# cyt4dn register map
Vendor: Cypress Semiconductor; Series: cyt4dn; File version: 1.0
CPU: CM7 r0p1, little endian, MPU, FPU, VTOR, 3 interrupt priority bits
Registers are 32-bit, read-write, reset 0x0 unless marked. A register's access mark holds for its fields unless they carry their own. Offsets are from the block's base; [hi:lo] are bit positions; lines under a group give offsets from that group; {n}, {i} and the like mark numbered series; 'fields as' and 'values as' point back to an identical list.

## VIDEOSS0 (part 10 of 18) — Video and Graphics Subsystem IP
Base 0x40A00000
0x80000 VIDEOIO group — Video I/O Core
  0x00 SUBIO group — Sub Interface
    0x10000 COMPENG group — Composition Engine
      0x7000 GPSCALER4 group — GPscaler #4 (Capture)
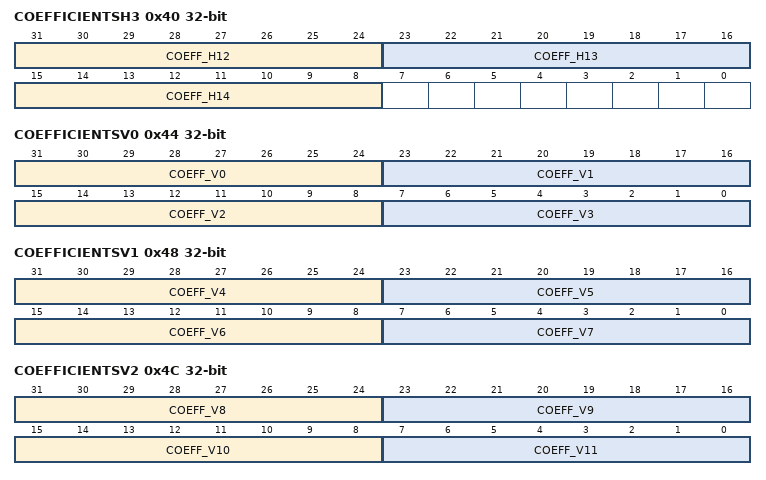
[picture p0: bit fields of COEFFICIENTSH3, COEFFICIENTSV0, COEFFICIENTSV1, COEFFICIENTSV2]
        0x40 COEFFICIENTSH3 — Horizontal coefficients for filter_mode FIR.
          [31:24] COEFF_H12 — Horizontal coefficient 12. (format is signed integer)
          [23:16] COEFF_H13 — Horizontal coefficient 13. (format is signed integer)
          [15:8] COEFF_H14 — Horizontal coefficient 14. The rightmost coefficient regardless of the filter width. In contrast to the coeff_h0 this coefficient has to be always programmed. (format is signed integer)
        0x44 COEFFICIENTSV0 — Vertical coefficients for filter_mode FIR.
          [31-8n:24-8n] COEFF_V{n} (n=0..3) — Vertical coefficient {n}. (format is signed integer)
        0x48 COEFFICIENTSV1 — Vertical coefficients for filter_mode FIR.
          [63-8n:56-8n] COEFF_V{n} (n=4..7) — Vertical coefficient {n}. (format is signed integer)
        0x4C COEFFICIENTSV2 — Vertical coefficients for filter_mode FIR.
          [95-8n:88-8n] COEFF_V{n} (n=8..11) — Vertical coefficient {n}. (format is signed integer)
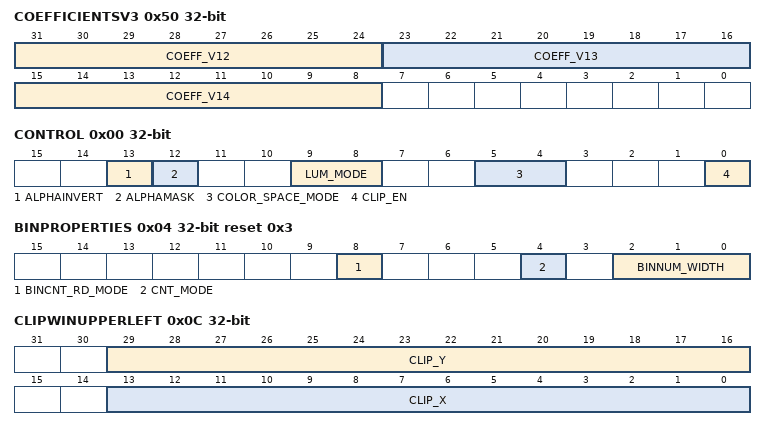
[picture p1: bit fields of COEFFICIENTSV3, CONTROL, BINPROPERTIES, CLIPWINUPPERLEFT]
        0x50 COEFFICIENTSV3 — Vertical coefficients for filter_mode FIR.
          [31:24] COEFF_V12 — Vertical coefficient 12. (format is signed integer)
          [23:16] COEFF_V13 — Vertical coefficient 13. (format is signed integer)
          [15:8] COEFF_V14 — Vertical coefficient 14. The bottommost coefficient regardless of the filter height. In contrast to the coeff_v0 this coefficient has to be always programmed. (format is signed integer)
      0x7400 HISTOGRAM4 group — Video Processing Block #0 Histogram (Capture)
        0x00 CONTROL — Controls some settings concerning input components and alpha mask.
          [13] ALPHAINVERT — Value 1 inverts the effect of the alpha mask mode when enabled (pixels with alpha value smaller or equal 0.5 are affecting the histogram bins).
          [12] ALPHAMASK — Value 1 enables the alpha mask mode. In this mode only pixels with an alpha value larger than 0.5 are affecting the histogram bins.
          [9:8] LUM_MODE — If a histogram for luma or luminance is required, the conversion formula for luma (Y component according to BT.601) or luminance (Y component according to BT.709) can be selected here. Luma or luminance calculation should only be applied if RGB components in range [0..255] are delivered directly at histogram input or when YCrCb components are converted to RGB by the appropriate setting of register field color_space_mode. Luma or luminance counting is delivered in first (component0) histogram. (format is unsigned integer)
            0=NO_CONV (Component0 for first histogram is counted as it is.); 1=LUMA (Component0 for first histogram is replaced by luma, which is calculated from RGB input components according to BT.601.); 2=LUMINANCE (Component0 for first histogram is replaced by luminance, which is calculated from RGB input components according to BT.709.)
          [5:4] COLOR_SPACE_MODE — Assuming that YUV(YCrCb) color components according to BT.601 or BT.709 are provided at histogram input the appropriate conversion to RGB components in [0,255] range can be selected here. (format is unsigned integer)
            0=NO_CONV (No color space conversion of input components is applied.); 1=YUV2RGB_BT601 (YUV input components as described in BT.601 are converted to RGB in [0,255] range.); 2=YUV2RGB_BT709 (YUV input components as described in BT.709 are converted to RGB in [0,255] range.)
          [0] CLIP_EN — Switch for clip window. If enabled all pixels outside the clip window are not taken into account. (format is unsigned integer)
            0=DISABLE (Clip window is switched off.); 1=ENABLE (Clip window is switched on.)
        0x04 BINPROPERTIES reset 0x3 — Configures the histogram bins.
          [8] BINCNT_RD_MODE — The field controls if the actual bin count or the sum of all bin counts up to actual bin count is provided in registers RsltComp0Bincnt, RsltComp1Bincnt and RsltComp2Bincnt. (format is unsigned integer)
            0=BINCNT (Actual bin cnt is provided.); 1=BINCNT_ACCU (Bin count sum is provided.)
          [4] CNT_MODE — Counter mode, which controls the way the bin values are accumulated. (format is unsigned integer)
            0=NEAREST (Counter of nearest bin is incremented.); 1=LINEAR (Counters of the 2 nearest bins are increased by one minus the distance to bin center (normalized between 0 and 1), it works only for first (component0) histogram, reading of component1/2 histogram results in undefined data.)
          [2:0] BINNUM_WIDTH — 2**binnum_width is the number of bins in a histogram. (format is unsigned integer)
            3=BINS_8 (There are 8 bins, addressable with 3bit.); 4=BINS_16 (There are 16 bins, addressable with 4bit.); 5=BINS_32 (There are 32 bins, addressable with 5bit.); 6=BINS_64 (There are 64 bins, addressable with 6bit.)
        0x08 BINCNTTHRESH — Bin counter threshold value.
          [28:0] BINCNT_THRESH — Bin counters below this threshold will be reported as 0. This threshold value will also affect the BINCNT_ACCU mode where 0 will be added for all bin counters below the threshold. (format is unsigned integer)
        0x0C CLIPWINUPPERLEFT — Coordinates of upper left corner of clip window.
          [29:16] CLIP_Y — Y coordinate of upper left corner of clip window. (format is unsigned integer)
          [13:0] CLIP_X — X coordinate of upper left corner of clip window. (format is unsigned integer)
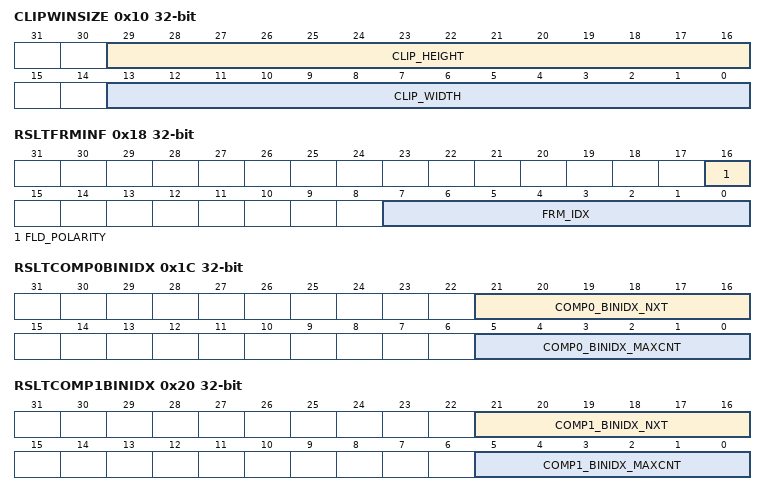
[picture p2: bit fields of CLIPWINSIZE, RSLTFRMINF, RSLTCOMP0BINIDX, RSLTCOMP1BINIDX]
        0x10 CLIPWINSIZE — Dimensions of clip window.
          [29:16] CLIP_HEIGHT — Height of clip window, given minus one. (format is unsigned integer)
          [13:0] CLIP_WIDTH — Width of clip window, given minus one. (format is unsigned integer)
        0x14 RSLTRDY ro — Measurement result status.
          [0] RSLT_RDY — A one indicates that measurement results (in registers Rslt...) are valid and can be read. (format is unsigned integer)
        0x18 RSLTFRMINF ro — Additional information on the measurement results.
          [16] FLD_POLARITY — Returns field polarity of the measured frame. This read value of this field is undefined in display stream context; use in storage, content or safety stream context only. (format is unsigned integer)
          [7:0] FRM_IDX — Each frame passing the histogram unit gets an index, which is the value of a wrapped around counter, which counts the frames independent from how the histogram unit is configured. The index of the frame of the ongoing readout can be read here. In display stream context, if the display operation ends (framegen is switched off and sequence complete occurs) this frame index is reset to 0. (format is unsigned integer)
        0x1C RSLTCOMP0BINIDX ro — Results of frame measurement for component 0.
          [21:16] COMP0_BINIDX_NXT — Do not use this filed. The index of the bin, that will be next accessed by register RsltComp0Bincnt. In the case of RGB pixels, component0 means the red value, in the case of YUV pixels, component 0 means the Y value. If luma/luminance calculation is switched on by field lum_mode component0 is the calculated luma/luminance. (format is unsigned integer)
          [5:0] COMP0_BINIDX_MAXCNT — The index of the bin of the component 0 histogram, which contains the highest counter value, which were read until now for the ongoing readout. In the case of RGB pixels, component 0 means the red value, in the case of YUV pixels, component0 means the Y value. If luma/luminance calculation is switched on by field lum_mode component0 is the calculated luma/luminance. (format is unsigned integer)
        0x20 RSLTCOMP1BINIDX ro — Results of frame measurement for component 1.
          [21:16] COMP1_BINIDX_NXT — The index of the bin, that will be next accessed by register RsltComp1Bincnt. In the case of RGB pixels, component 1 means the green value. In the case of YUV pixels, component 1 means the Cb value. (format is unsigned integer)
          [5:0] COMP1_BINIDX_MAXCNT — The index of the bin of the component 1 histogram, which contains the highest counter value, which were read until now for the ongoing readout. In the case of RGB pixels, component 1 means the green value. In the case of YUV pixels, component 1 means the Cb value. (format is unsigned integer)
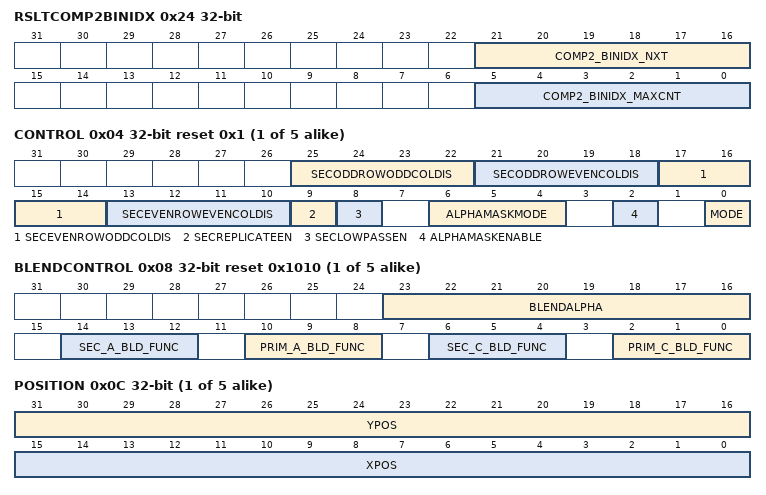
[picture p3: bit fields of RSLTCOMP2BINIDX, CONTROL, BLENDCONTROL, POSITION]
        0x24 RSLTCOMP2BINIDX ro — Results of frame measurement for component 2.
          [21:16] COMP2_BINIDX_NXT — The index of the bin, that will be next accessed by register RsltComp2Bincnt. In the case of RGB pixels, component 2 means the blue value. In the case of YUV pixels, component 2 means the Cr value. (format is unsigned integer)
          [5:0] COMP2_BINIDX_MAXCNT — The index of the bin of the component 2 histogram, which contains the highest counter value, which were read until now for the ongoing readout. In the case of RGB pixels, component 2 means the blue value. In the case of YUV pixels, component 2 means the Cr value. (format is unsigned integer)
        0x28 RSLTCOMP0SUM ro — Sum of all component 0 values.
          [31:0] COMP0_SUM — Sum of all component 0 values. In the case of RGB pixels, component 0 means the red value, in the case of YUV pixels, component 0 means the Y value. If luma/luminance calculation is switched on by field lum_mode, component 0 is the calculated luma/luminance. If the read value is 0xFFFFFFFF a counter overflow has occurred and the read value should not be used (this can only happen for frame dimensions beyond 2^12 * 2^12). (format is unsigned integer)
        0x2C RSLTCOMP1SUM ro — Sum of all component 1 values.
          [31:0] COMP1_SUM — Sum of all component 1 values. In the case of RGB pixels, component 1 means the green value. In the case of YUV pixels, component 1 means the Cb value. If the read value is 0xFFFFFFFF a counter overflow has occurred and the read value should not be used (this can only happen for frame dimensions beyond 2^12 * 2^12). (format is unsigned integer)
        0x30 RSLTCOMP2SUM ro — Sum of all component 2 values.
          [31:0] COMP2_SUM — Sum of all component 2 values. In the case of RGB pixels, component 2 means the blue value. In the case of YUV pixels, component 2 means the Cr value. If the read value is 0xFFFFFFFF a counter overflow has occurred and the read value should not be used (this can only happen for frame dimensions beyond 2^12 * 2^12). (format is unsigned integer)
        0x34 RSLTCOMP0BINCNT ro — Bin counters of component 0 histogram. This register do NOT support debugger access followed by software access (they clear on read)
          [28:0] COMP0_BINCNT — Counter of current bin number in component 0 histogram. In the case of RGB pixels, component 0 means the red value, in the case of YUV pixels, component 0 means the Y value. (format is unsigned integer)
        0x38 RSLTCOMP1BINCNT ro — Bin counters of component 1 histogram. This register do NOT support debugger access followed by software access (they clear on read)
          [28:0] COMP1_BINCNT — Counter of current bin number in component 1 histogram. In the case of RGB pixels, component 1 means the green value. In the case of YUV pixels, component 1 means the Cb value. (format is unsigned integer)
        0x3C RSLTCOMP2BINCNT ro — Bin counters of component 2 histogram. This register do NOT support debugger access followed by software access (they clear on read)
          [28:0] COMP2_BINCNT — Counter of current bin index in component 2 histogram. In the case of RGB pixels, component 2 means the blue value. In the case of YUV pixels, component 2 means the Cb value. (format is unsigned integer)
        0x40 FRMSTRTTRIG wo reset not defined — Triggers for loading shadow registers and starting measurement with next input frame.
          [0] MSRMNT_STRT_TRIG — Writing value 1 into this field initiates the measurement of the next frame. (format is unsigned integer)
      {0x7400+0x400*l} LAYERBLEND{l} group (l=1..5) — LayerBlend #{l} (Display, Alpha Plane {l})
        0x00 STATICCONTROL reset 0x14 — Static control settings.
          [4:3] SHDTOKSEL — Controls when a shadow load token is generated on the output port, which controls shadow load in subsequent processing units.
            0=PRIMARY (When a token was received on the primary input (background plane).); 1=SECONDARY (When a token was received on the secondary input (foreground plane).); 2=BOTH (When a token was received on any input.)
          [2:1] SHDLDSEL — Controls when shadow fields of this unit are loaded into the active configuration in case that ShdEn is enabled.
            0=PRIMARY (Load shadows with shadow load token on primary input (background plane).); 1=SECONDARY (Load shadows with shadow load token on secondary input (foreground plane).); 2=BOTH (Load shadows with shadow load token on any input.)
          [0] SHDEN — Enables shadowing of all RWS type fields of this unit (0 = write through, 1 = shadowed).
        0x04 CONTROL reset 0x1 — Common control settings.
          [25:22] SECODDROWODDCOLDIS — Disable bits for R/Y, G/U, B/V and A channels of secondary input when row and column index is odd. R/Y is MSBit, A is LSBit.
          [21:18] SECODDROWEVENCOLDIS — Disable bits for R/Y, G/U, B/V and A channels of secondary input when row index is odd and column index is even. R/Y is MSBit, A is LSBit.
          [17:14] SECEVENROWODDCOLDIS — Disable bits for R/Y, G/U, B/V and A channels of secondary input when row index is even and column index is odd. R/Y is MSBit, A is LSBit.
          [13:10] SECEVENROWEVENCOLDIS — Disable bits for R/Y, G/U, B/V and A channels of secondary input when row and column index is even. R/Y is MSBit, A is LSBit.
          [9] SECREPLICATEEN — Enables horizontal replication of pixels by factor 2 on secondary input port. Must be used for dual display mode when the secondary input frame has the resolution of one display (= half the resolution of the panel interface).
          [8] SECLOWPASSEN — Enables a horizontal low-pass filter for the secondary input port. Should be used for dual view and dual display mode when the secondary input frame has twice the resolution of one view (= full resolution of the panel interface). Every 2nd pixel only is sampled then.
          [6:4] ALPHAMASKMODE — AlphaMaskMode determines how the output alpha is generated when AlphaMaskEnable is set to ENABLE
            0=PRIM (Areas with primary input alpha > 128 will be mapped to 255 and the rest will have an alpha value of 0); 1=SEC (The area of the secondary input will get an alpha value of 255 and the rest will be 0); 2=PRIM_OR_SEC (Behaves as if the output of modes PRIM and SEC would be ORed together); 3=PRIM_AND_SEC (Behaves as if the output of modes PRIM and SEC would be ANDed together); 4=PRIM_INV (Behaves as if the output of mode PRIM would be inverted); 5=SEC_INV (Behaves as if the output of mode SEC would be inverted); 6=PRIM_OR_SEC_INV (Behaves as if the output of modes PRIM and SEC_INV would be ORed together); 7=PRIM_AND_SEC_INV (Behaves as if the output of modes PRIM and SEC_INV would be ANDed together)
          [2] ALPHAMASKENABLE — Enables Alpha Mask feature. This will limit possible output alpha values to 0 and 255. Generation of this alpha value will depend on the AlphaMaskMode field.
            0=DISABLE (AlphaMask feature disabled); 1=ENABLE (AlphaMask feature enabled)
          [0] MODE — Operation mode.
            0=NEUTRAL (Module is in neutral mode. Output is same as primary input.); 1=BLEND (Module is in blending mode.)
        0x08 BLENDCONTROL reset 0x1010 — Options for blend operations
          [23:16] BLENDALPHA — Constant alpha value, used for constant alpha blending
          [14:12] SEC_A_BLD_FUNC — Secondary (overlay) input alpha blending function
            0=ZERO (Aout = Ain * 0); 1=ONE (Aout = Ain * 1); 2=PRIM_ALPHA (Aout = Ain * ALPHA_prim); 3=ONE_MINUS_PRIM_ALPHA (Aout = Ain * (1 - ALPHA_prim)); 4=SEC_ALPHA (Aout = Ain * ALPHA_sec); 5=ONE_MINUS_SEC_ALPHA (Aout = Ain * (1 - ALPHA_sec)); 6=CONST_ALPHA (Aout = Ain * ALPHA_const); 7=ONE_MINUS_CONST_ALPHA (Aout = Ain * (1 - ALPHA_const))
          [10:8] PRIM_A_BLD_FUNC — Primary (background) input alpha blending function
            values as SEC_A_BLD_FUNC
          [6:4] SEC_C_BLD_FUNC — Secondary (overlay) input color blending function
            0=ZERO (Cout = Cin * 0); 1=ONE (Cout = Cin * 1); 2=PRIM_ALPHA (Cout = Cin * ALPHA_prim); 3=ONE_MINUS_PRIM_ALPHA (Cout = Cin * (1 - ALPHA_prim)); 4=SEC_ALPHA (Cout = Cin * ALPHA_sec); 5=ONE_MINUS_SEC_ALPHA (Cout = Cin * (1 - ALPHA_sec)); 6=CONST_ALPHA (Cout = Cin * ALPHA_const); 7=ONE_MINUS_CONST_ALPHA (Cout = Cin * (1 - ALPHA_const))
          [2:0] PRIM_C_BLD_FUNC — Primary (background) input color blending function
            values as SEC_C_BLD_FUNC
        0x0C POSITION — Position of secondary (overlay) input frame
          [31:16] YPOS — vertical position, first pixel is at 0, format s15 (twos complement) (format is signed integer)
          [15:0] XPOS — horizontal position, first pixel is at 0, format s15 (twos complement) (format is signed integer)
      0x8C00 EXTSRC8 group — ExtSrc #8 (Display)
        0x00 STATICCONTROL — ExtSrc static control register
          [8] STARTSEL — Start select selects the mode to start processing operations.
            0=INPUT (Free running mode, use the incoming command word as trigger to start processing.); 1=LOCAL (Keep to local start configuration, use external kick or SW trigger to start processing. The behavior is similar to fetch units.)
          [0] SHDEN — Enables shadowing of all RWS type registers (0=write_through, 1=shadowed).
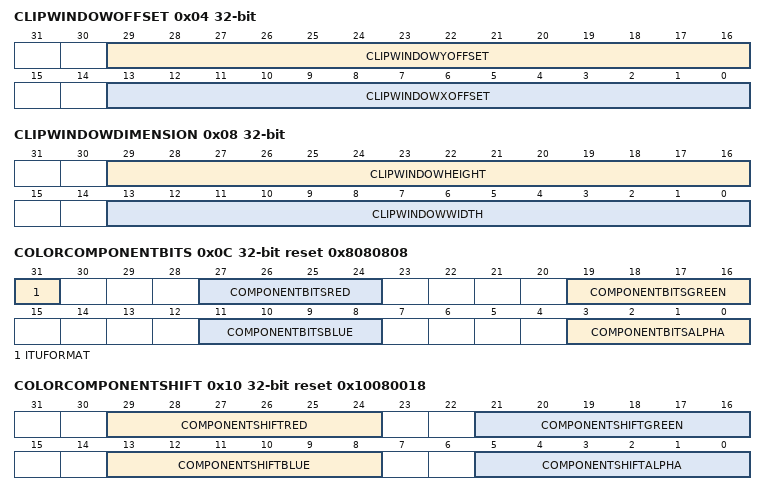
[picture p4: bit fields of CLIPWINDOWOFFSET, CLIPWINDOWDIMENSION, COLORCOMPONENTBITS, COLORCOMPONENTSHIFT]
        0x04 CLIPWINDOWOFFSET — Clip window offset, to generate a clipping of the frame. It has to be within the input frame.
          [29:16] CLIPWINDOWYOFFSET — Clip window offset in Y direction, relative to the frame origin.
          [13:0] CLIPWINDOWXOFFSET — Clip window offset in X direction, relative to the frame origin.
        0x08 CLIPWINDOWDIMENSION — Define the clip window dimension. If the clip window feature is enabled this dimension is used for the new frame dimension. Note that the clip window has to be smaller or equal to the original frame dimensions. The new frame has to be within the active area of the original frame.
          [29:16] CLIPWINDOWHEIGHT — Clip window height in pixels minus one.
          [13:0] CLIPWINDOWWIDTH — Clip window width in pixels minus one.
        0x0C COLORCOMPONENTBITS reset 0x8080808 — Color component size of raw input data. Please note that the width must be equal or lower than the output width.
          [31] ITUFORMAT — When ComponentBitsRed/Green/Blue is set to 10 and this mode enabled (value 1), then input format is considered 8.2 instead of 10.0 bits (max color is 1020 instead of 1023). This is compliant to ITU 656 standard.
          [27:24] COMPONENTBITSRED — Component size of red channel [0-10].
          [19:16] COMPONENTBITSGREEN — Component size of green channel [0-10].
          [11:8] COMPONENTBITSBLUE — Component size of blue channel [0-10].
          [3:0] COMPONENTBITSALPHA — Component size of alpha channel [0-8].
        0x10 COLORCOMPONENTSHIFT reset 0x10080018 — Color component offset of raw input data.
          [29:24] COMPONENTSHIFTRED — Offset for red component.
          [21:16] COMPONENTSHIFTGREEN — Offset for green component.
          [13:8] COMPONENTSHIFTBLUE — Offset for blue component.
          [5:0] COMPONENTSHIFTALPHA — Offset for alpha component.
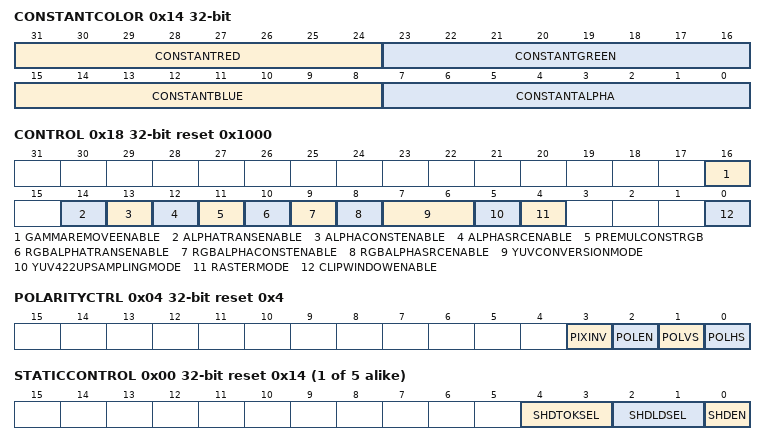
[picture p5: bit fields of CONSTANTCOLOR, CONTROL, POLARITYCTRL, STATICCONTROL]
        0x14 CONSTANTCOLOR
          [31:24] CONSTANTRED — Red or Y (luma).
          [23:16] CONSTANTGREEN — Green or U (chroma).
          [15:8] CONSTANTBLUE — Blue or V (chroma).
          [7:0] CONSTANTALPHA — Alpha.
        0x18 CONTROL reset 0x1000 — Common control settings.
          [16] GAMMAREMOVEENABLE — Value 1 enables the stage to remove a gamma from RGB components.
          [14] ALPHATRANSENABLE — Value 1 enables transparent alpha for computing the output alpha. When disabled transparent alpha is set to 1.
          [13] ALPHACONSTENABLE — Value 1 enables constant alpha for computing the output alpha. When disabled constant alpha is set to 1.
          [12] ALPHASRCENABLE — Value 1 enables source alpha for computing the output alpha. When disabled source alpha is set to 1.
          [11] PREMULCONSTRGB — When enabled (value 1) the values given by ConstantRed/Green/Blue are used instead of alpha for source RGB pre-multiply. Settings RGBAlphaSrc/Const/TransEnable have no effect then.
          [10] RGBALPHATRANSENABLE — Value 1 enables transparent alpha (0 or 1 depending on RGB matching ConstantColor setting) for RGB pre-multiply. When disabled transparent alpha is set to 1.
          [9] RGBALPHACONSTENABLE — Value 1 enables constant alpha (ConstAlpha field) for RGB pre-multiply. When disabled constant alpha is set to 1.
          [8] RGBALPHASRCENABLE — Value 1 enables source alpha (extracted from input stream) for RGB pre-multiply. When disabled source alpha is set to 1.
          [7:6] YUVCONVERSIONMODE — Enables different kind of YUV to RGB conversions.
            0=OFF (No conversion. Input data must be RGB.); 1=ITU601 (Conversion from YCbCr (YUV) to RGB according to ITU recommendation BT.601-6 (standard definition TV). Input range is 16..235 for Y and 16..240 for U/V.); 2=ITU601_FR (Conversion from YCbCr (YUV) to RGB according to ITU recommendation BT.601-6, but assuming full range YUV inputs (0..255). Most typically used for computer graphics (e.g. for JPEG encoding).); 3=ITU709 (Conversion from YCbCr (YUV) to RGB according to ITU recommendation BT.709-5 part 2 (high definition TV). Input range is 16..235 for Y and 16..240 for U/V.)
          [5] YUV422UPSAMPLINGMODE — Selects a method for horizontal up-sampling when RasterMode is YUV422.
            0=REPLICATE (Replicate mode for interspersed samples (UV samples between Y samples).); 1=INTERPOLATE (Interpolate mode for coaligned samples (UV samples at Y sample positions).)
          [4] RASTERMODE — Selects a method how generate output samples from input stream.
            0=NORMAL (Input stream is RGB(A) or YUV 4:4:4.); 1=YUV422 (Input stream is packed YUV 4:2:2.)
          [0] CLIPWINDOWENABLE — Value 1 enables the clip window feature.
        0x1C CONTROLTRIGGER wo reset not defined — ExtSrc unit trigger token generation
          [0] SHDTOKGEN — Write a 1 to this field for the extsrc unit to perform a shadow load with the next start of operation and set the rld bit in the start of frame control word (generate shadow load token for subsequent units).
        0x20 START wo reset not defined — ExtSrc unit start register
          [0] START — Writing a one starts processing, use this only for debug purposes.
  0x20000 DISENG0 group — Display Engine
    0x00 DISENGCFG0 group — Top-Level Configuration
      0x00 CTL reset 0x1 — Display engine control register.
        [0] DSPCLKDIVIDE — Controls generation of display clock signals for display stream.
          0=DIV1 (External display clock signal has pixel clock frequency.); 1=DIV2 (External display clock signal has twice the pixel clock frequency.)
      0x04 POLARITYCTRL reset 0x4 — Polarity control for TCon input and corresponding top-level output (TCon by-pass port).
        [3] PIXINV — Inversion of RGB data.
          0=NONINV (No inversion of pixel data); 1=INV (Pixel data inverted (1. complement))
        [2] POLEN — Polarity of Data_Enable signal.
          0=LOW (Low active); 1=HIGH (High active)
        [1] POLVS — Polarity of vsync signal.
          0=LOW (Low active); 1=HIGH (High active)
        [0] POLHS — Polarity of hsync signal.
          0=LOW (Low active); 1=HIGH (High active)
      0x10 SIGSELECT — Tap selection for Signature.
        [1:0] SIG_SELECT — Selects a source for Sig unit.
          0=NONE (No source.); 1=FRAMEGEN (Source is FrameGen output.); 2=GAMMACOR (Source is GammaCor output.); 3=DITHER (Source is Dither output.)
      0x20 DUMPSELECT — Tap selection for Frame Dump.
        [9:8] DUMP_SELECT — Selects a source for FrameDump unit.
          values as VIDEOIO.DISENG0.DISENGCFG0.SIGSELECT.SIG_SELECT
    0x1000 SIG0 group — Signature Unit
      0x00 STATICCONTROL reset 0x8000000 — Global configuration shared by all evaluation windows.
        [31:24] ERRTHRESRESET — ErrThresReset must be programmed to value less than 255. Number of consecutive frames without signature violation before StsSigError is reset for an evaluation window. 0 means that each frame without violation will reset the status. The internal counter compared against this threshold is reset with each frame that has violation.
        [23:16] ERRTHRES — Number of frames with signature violation before StsSigError is set for an evaluation window. These frames do not need to be consecutive. 0 means that each frame with violation will set the status. The internal counter compared against this threshold is reset when 'ErrThreshReset' consecutive frames without signature violation occur.
        [4] SHDLDSEL — Source select for events that will load shadow registers into the active configuration.
          0=LOCAL (Shadows are loaded at start of frame for each evaluation window for which ShdLdReq has been set.); 1=GLOBAL (Shadows of all evaluation windows are loaded synchronous to the display stream (shadow load token received on frame input port).)
        [0] SHDEN — Enables shadow registers for RWS type fields (0 = write through, 1 = shadowed).
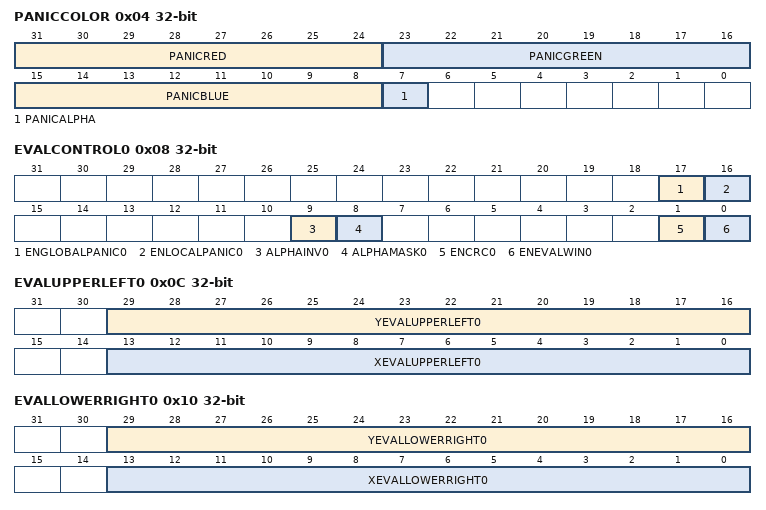
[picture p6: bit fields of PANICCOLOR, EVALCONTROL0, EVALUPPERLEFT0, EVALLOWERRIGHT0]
      0x04 PANICCOLOR — Overlay color for evaluation windows in panic mode.
        [31:24] PANICRED — Red color component.
        [23:16] PANICGREEN — Green color component.
        [15:8] PANICBLUE — Blue color component.
        [7] PANICALPHA — Alpha mask bit.
      0x08 EVALCONTROL0 — Control settings for evaluation window 0.
        [17] ENGLOBALPANIC0 — When enabled (value 1) the error status of this window (StsSigError) will activate the panic mode of the display stream's Frame Generator, which can switch to another display mode in response.
        [16] ENLOCALPANIC0 — When enabled (value 1) the error status this window (StsSigError) will replace all pixels inside the window by a constant color on the display. Skip regions due to other evaluation windows on top are not modified. AlphaMask, when enabled, is not considered for this replacement.
        [9] ALPHAINV0 — When enabled (value 1) the effect of AlphaMask is inverted (pixels with alpha bit = 1 are ignored then).
        [8] ALPHAMASK0 — When enabled (value 1) pixels with alpha bit = 0 are ignored for signature computation.
        [1] ENCRC0 — When enabled (value 1) the measured signature is checked against a reference value (SigCRCRef).
        [0] ENEVALWIN0 — When enabled (value 1) a CRC signature is computed for all pixels inside this evaluation window (SigCRC). When this bit is cleared, the internal status for this window is reset (StsSigError bit and frame counters).
      0x0C EVALUPPERLEFT0 — Upper left corner of evaluation window 0.
        [29:16] YEVALUPPERLEFT0 — Y coordinate.
        [13:0] XEVALUPPERLEFT0 — X coordinate.
      0x10 EVALLOWERRIGHT0 — Lower right corner of evaluation window 0.
        [29:16] YEVALLOWERRIGHT0 — Y coordinate.
        [13:0] XEVALLOWERRIGHT0 — X coordinate.
      0x14 SIGCRCREDREF0 reset 0xFFFFFFFF — Reference signature of red channel for evaluation window 0.
        [31:0] SIGCRCREDREF0 — Reference value that is compared against measured SigCRCRed value.
      0x18 SIGCRCGREENREF0 reset 0xFFFFFFFF — Reference signature of green channel for evaluation window 0.
        [31:0] SIGCRCGREENREF0 — Reference value that is compared against measured SigCRCGreen value.
      0x1C SIGCRCBLUEREF0 reset 0xFFFFFFFF — Reference signature of blue channel for evaluation window 0.
        [31:0] SIGCRCBLUEREF0 — Reference value that is compared against measured SigCRCBlue value.
      0x20 SIGCRCRED0 ro reset 0xFFFFFFFF — Measured signature of red channel for evaluation window 0.
        [31:0] SIGCRCRED0 — CRC values from red channel.
      0x24 SIGCRCGREEN0 ro reset 0xFFFFFFFF — Measured signature of green channel for evaluation window 0.
        [31:0] SIGCRCGREEN0 — CRC values from green channel.
      0x28 SIGCRCBLUE0 ro reset 0xFFFFFFFF — Measured signature of blue channel for evaluation window 0.
        [31:0] SIGCRCBLUE0 — CRC values from blue channel.
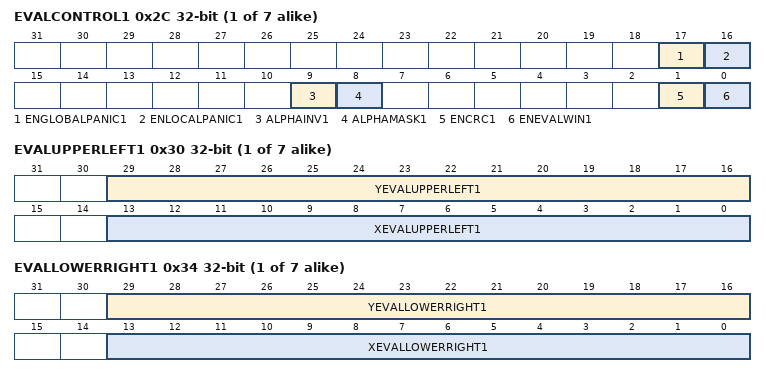
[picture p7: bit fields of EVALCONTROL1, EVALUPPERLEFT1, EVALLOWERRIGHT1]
      {0x8+0x24*l} EVALCONTROL{l} (l=1..7) — Control settings for evaluation window {l}.
        [17] ENGLOBALPANIC{l} — See EnGlobalPanic0.
        [16] ENLOCALPANIC{l} — See EnLocalPanic0.
        [9] ALPHAINV{l} — See AlphaInv0.
        [8] ALPHAMASK{l} — See AlphaMask0.
        [1] ENCRC{l} — See EnCRC0.
        [0] ENEVALWIN{l} — See EnEvalWin0.
      {0xC+0x24*l} EVALUPPERLEFT{l} (l=1..7) — Upper left corner of evaluation window {l}.
        [29:16] YEVALUPPERLEFT{l} — See YEvalUpperLeft0.
        [13:0] XEVALUPPERLEFT{l} — See XEvalUpperLeft0.
      {0x10+0x24*l} EVALLOWERRIGHT{l} (l=1..7) — Lower right corner of evaluation window {l}.
        [29:16] YEVALLOWERRIGHT{l} — See YEvalLowerRight0.
        [13:0] XEVALLOWERRIGHT{l} — See XEvalLowerRight0.
      {0x14+0x24*l} SIGCRCREDREF{l} reset 0xFFFFFFFF (l=1..7) — Reference signature of red channel for evaluation window {l}.
        [31:0] SIGCRCREDREF{l} — See SigCRCRedRef0.
      {0x18+0x24*l} SIGCRCGREENREF{l} reset 0xFFFFFFFF (l=1..7) — Reference signature of green channel for evaluation window {l}.
        [31:0] SIGCRCGREENREF{l} — See SigCRCGreenRef0.
      {0x1C+0x24*l} SIGCRCBLUEREF{l} reset 0xFFFFFFFF (l=1..7) — Reference signature of blue channel for evaluation window {l}.
        [31:0] SIGCRCBLUEREF{l} — See SigCRCBlueRef0.
